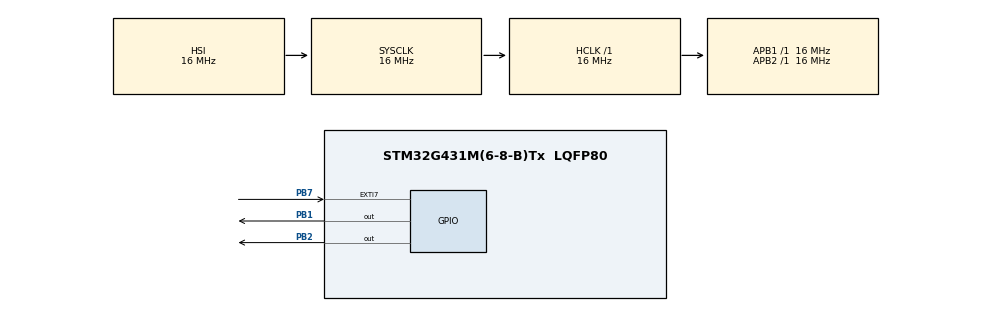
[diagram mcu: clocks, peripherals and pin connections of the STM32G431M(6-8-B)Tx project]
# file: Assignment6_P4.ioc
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Mcu.Family=STM32G4
Mcu.Name=STM32G431M(6-8-B)Tx
Mcu.Package=LQFP80
NVIC.EXTI9_5_IRQn=true\:0\:0\:false\:false\:true\:true\:true\:true
NVIC.PriorityGroup=NVIC_PRIORITYGROUP_4
PB1.PinState=GPIO_PIN_SET
PB1.Signal=GPIO_Output
PB2.PinState=GPIO_PIN_SET
PB2.Signal=GPIO_Output
PB7.GPIO_ModeDefaultEXTI=GPIO_MODE_IT_FALLING
PB7.GPIO_PuPd=GPIO_PULLUP
PB7.Signal=GPXTI7
ProjectManager.HeapSize=0x200
ProjectManager.StackSize=0x400
ProjectManager.TargetToolchain=STM32CubeIDE
RCC.AHBFreq_Value=16000000
RCC.APB1Freq_Value=16000000
RCC.APB1TimFreq_Value=16000000
RCC.APB2Freq_Value=16000000
RCC.APB2TimFreq_Value=16000000
RCC.CortexFreq_Value=16000000
RCC.EXTERNAL_CLOCK_VALUE=12288000
RCC.HCLKFreq_Value=16000000
RCC.HSE_VALUE=8000000
RCC.HSI48_VALUE=48000000
RCC.HSI_VALUE=16000000
RCC.LSE_VALUE=32768
RCC.SYSCLKFreq_VALUE=16000000
RCC.USBFreq_Value=64000000
RCC.VCOOutputFreq_Value=128000000
board=custom

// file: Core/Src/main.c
/* USER CODE BEGIN Header */
/**
  ******************************************************************************
  * @file           : main.c
  * @brief          : Main program body
  ******************************************************************************
  * @attention
  *
  * Copyright (c) 2025 STMicroelectronics.
  * All rights reserved.
  *
  * This software is licensed under terms that can be found in the LICENSE file
  * in the root directory of this software component.
  * If no LICENSE file comes with this software, it is provided AS-IS.
  *
  ******************************************************************************
  */
/* USER CODE END Header */
#include "main.h"

void SystemClock_Config(void);
static void MX_GPIO_Init(void);

/* USER CODE BEGIN 0 */

//Interrupt callback function to read Button pressed state
void HAL_GPIO_EXTI_Callback(uint16_t GPIO_Pin){

	while(1){

	//if button 1 is pressed, turns ON Green LED and Turns OFF Red LED
	if(HAL_GPIO_ReadPin(GPIOB, GPIO_PIN_7) == 0){
		HAL_GPIO_WritePin(GPIOB, GPIO_PIN_1, 0); //Turns ON Green LED
		HAL_GPIO_WritePin(GPIOB, GPIO_PIN_2, 1); //Turns OFF RED LED
	}

	//if button 1 is not pressed, turns OFF Green LED and Turns ON Red LED
	if (HAL_GPIO_ReadPin(GPIOB, GPIO_PIN_7) == 1){
		HAL_GPIO_WritePin(GPIOB, GPIO_PIN_2, 0); //Turns ON Red LED
		HAL_GPIO_WritePin(GPIOB, GPIO_PIN_1, 1); //Turns OFF Green LED
	}
	HAL_GPIO_EXTI_IRQHandler(GPIO_PIN_7); // calls interrupt to check Button 1 status
	}
}

/* USER CODE END 0 */

int main(void)
{

  /* MCU Configuration--------------------------------------------------------*/

  /* Reset of all peripherals, Initializes the Flash interface and the Systick. */
  HAL_Init();

  /* Configure the system clock */
  SystemClock_Config();

  /* Initialize all configured peripherals */
  MX_GPIO_Init();
  /* USER CODE BEGIN 2 */

  //default RED LED to be ON
  HAL_GPIO_WritePin(GPIOB, GPIO_PIN_2, 0);
  /* USER CODE END 2 */

  /* Infinite loop */
  while (1)
  {

  }
}

void SystemClock_Config(void)
{
  RCC_OscInitTypeDef RCC_OscInitStruct = {0};
  RCC_ClkInitTypeDef RCC_ClkInitStruct = {0};

  /** Configure the main internal regulator output voltage
  */
  HAL_PWREx_ControlVoltageScaling(PWR_REGULATOR_VOLTAGE_SCALE1);

  /** Initializes the RCC Oscillators according to the specified parameters
  * in the RCC_OscInitTypeDef structure.
  */
  RCC_OscInitStruct.OscillatorType = RCC_OSCILLATORTYPE_HSI;
  RCC_OscInitStruct.HSIState = RCC_HSI_ON;
  RCC_OscInitStruct.HSICalibrationValue = RCC_HSICALIBRATION_DEFAULT;
  RCC_OscInitStruct.PLL.PLLState = RCC_PLL_NONE;
  if (HAL_RCC_OscConfig(&RCC_OscInitStruct) != HAL_OK)
  {
    Error_Handler();
  }

  /** Initializes the CPU, AHB and APB buses clocks
  */
  RCC_ClkInitStruct.ClockType = RCC_CLOCKTYPE_HCLK|RCC_CLOCKTYPE_SYSCLK
                              |RCC_CLOCKTYPE_PCLK1|RCC_CLOCKTYPE_PCLK2;
  RCC_ClkInitStruct.SYSCLKSource = RCC_SYSCLKSOURCE_HSI;
  RCC_ClkInitStruct.AHBCLKDivider = RCC_SYSCLK_DIV1;
  RCC_ClkInitStruct.APB1CLKDivider = RCC_HCLK_DIV1;
  RCC_ClkInitStruct.APB2CLKDivider = RCC_HCLK_DIV1;

  if (HAL_RCC_ClockConfig(&RCC_ClkInitStruct, FLASH_LATENCY_0) != HAL_OK)
  {
    Error_Handler();
  }
}

static void MX_GPIO_Init(void)
{
  GPIO_InitTypeDef GPIO_InitStruct = {0};

  /* GPIO Ports Clock Enable */
  __HAL_RCC_GPIOB_CLK_ENABLE();

  /*Configure GPIO pin Output Level */
  HAL_GPIO_WritePin(GPIOB, GPIO_PIN_1|GPIO_PIN_2, GPIO_PIN_SET);

  /*Configure GPIO pins : PB1 PB2 */
  GPIO_InitStruct.Pin = GPIO_PIN_1|GPIO_PIN_2;
  GPIO_InitStruct.Mode = GPIO_MODE_OUTPUT_PP;
  GPIO_InitStruct.Pull = GPIO_NOPULL;
  GPIO_InitStruct.Speed = GPIO_SPEED_FREQ_LOW;
  HAL_GPIO_Init(GPIOB, &GPIO_InitStruct);

  /*Configure GPIO pin : PB7 */
  GPIO_InitStruct.Pin = GPIO_PIN_7;
  GPIO_InitStruct.Mode = GPIO_MODE_IT_FALLING;
  GPIO_InitStruct.Pull = GPIO_PULLUP;
  HAL_GPIO_Init(GPIOB, &GPIO_InitStruct);

  /* EXTI interrupt init*/
  HAL_NVIC_SetPriority(EXTI9_5_IRQn, 0, 0);
  HAL_NVIC_EnableIRQ(EXTI9_5_IRQn);

}

void Error_Handler(void)
{
  __disable_irq();
  while (1)
  {
  }
}
